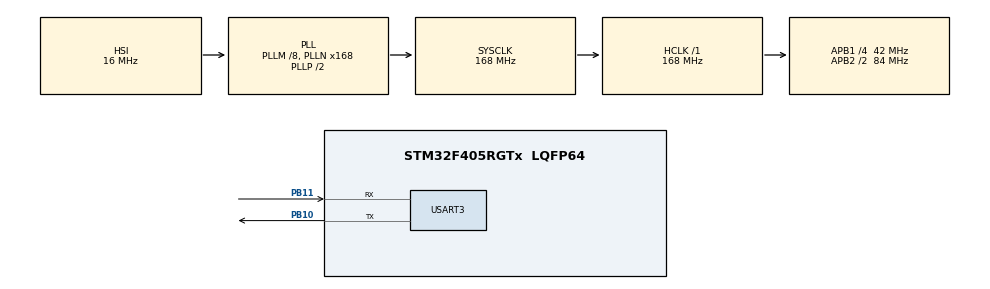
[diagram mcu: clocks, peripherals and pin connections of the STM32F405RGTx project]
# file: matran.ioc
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Mcu.Family=STM32F4
Mcu.Name=STM32F405RGTx
Mcu.Package=LQFP64
NVIC.PriorityGroup=NVIC_PRIORITYGROUP_4
PA13.Mode=Serial_Wire
PA13.Signal=SYS_JTMS-SWDIO
PA14.Mode=Serial_Wire
PA14.Signal=SYS_JTCK-SWCLK
PB10.Mode=Asynchronous
PB10.Signal=USART3_TX
PB11.Mode=Asynchronous
PB11.Signal=USART3_RX
PH0-OSC_IN.Mode=HSE-External-Oscillator
PH0-OSC_IN.Signal=RCC_OSC_IN
PH1-OSC_OUT.Mode=HSE-External-Oscillator
PH1-OSC_OUT.Signal=RCC_OSC_OUT
ProjectManager.HeapSize=0x200
ProjectManager.StackSize=0x400
ProjectManager.TargetToolchain=STM32CubeIDE
RCC.48MHZClocksFreq_Value=84000000
RCC.AHBFreq_Value=168000000
RCC.APB1CLKDivider=RCC_HCLK_DIV4
RCC.APB1Freq_Value=42000000
RCC.APB1TimFreq_Value=84000000
RCC.APB2CLKDivider=RCC_HCLK_DIV2
RCC.APB2Freq_Value=84000000
RCC.APB2TimFreq_Value=168000000
RCC.CortexFreq_Value=168000000
RCC.HCLKFreq_Value=168000000
RCC.HSE_VALUE=12000000
RCC.HSI_VALUE=16000000
RCC.LSE_VALUE=32768
RCC.PLLM=8
RCC.PLLN=168
RCC.SYSCLKFreq_VALUE=168000000
RCC.SYSCLKSource=RCC_SYSCLKSOURCE_PLLCLK
RCC.VCOOutputFreq_Value=336000000
USART3.VirtualMode=VM_ASYNC
board=custom

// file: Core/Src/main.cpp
/*
 * main.cpp
 *
 *  Created on: Feb 7, 2020
 *      Author: tung
 */
/* USER CODE BEGIN Header */
/**
  ******************************************************************************
  * @file           : main.c
  * @brief          : Main program body
  ******************************************************************************
  * @attention
  *
  * <h2><center>&copy; Copyright (c) 2020 STMicroelectronics.
  * All rights reserved.</center></h2>
  *
  * This software component is licensed by ST under BSD 3-Clause license,
  * the "License"; You may not use this file except in compliance with the
  * License. You may obtain a copy of the License at:
  *                        opensource.org/licenses/BSD-3-Clause
  *
  ******************************************************************************
  */
/* USER CODE END Header */

#include "main.h"

/* USER CODE BEGIN Includes */
#include "Matrix.hpp"
/* USER CODE END Includes */

void SystemClock_Config(void);
static void MX_GPIO_Init(void);
static void MX_USART3_UART_Init(void);

/* USER CODE BEGIN 0 */
UART_HandleTypeDef huart3;
/* USER CODE END 0 */

int main(void)
{

  /* MCU Configuration--------------------------------------------------------*/

  /* Reset of all peripherals, Initializes the Flash interface and the Systick. */
  HAL_Init();

  /* Configure the system clock */
  SystemClock_Config();

  /* Initialize all configured peripherals */
  MX_GPIO_Init();
  MX_USART3_UART_Init();
  /* USER CODE BEGIN 2 */
  double x [7] = {1,1,1,1,1,1,1};
  double a [9] = {0,1,2,3,4,5,6,7,8};
  double Q[49]= {  1,0,0,0,0,0,0,
          0,1,0,0,0,0, 0,
           0,0,3,0,0,0,0,
            0,0,0,4,0,0,0,
  		  0,0, 0 ,0 ,5 ,0, 0,
            0,0,0,0,0,6,0,
            0,0,0,0,0,0,7};
  /* USER CODE END 2 */
  Matrix q = Matrix(7,7);
  Matrix s_trans = Matrix(4,3);
  Matrix in = Matrix(3,3);
  in.get_value(a);
  Matrix temp = inverse(in);
  temp.print(huart3);
  Matrix x_ = Matrix(1,7);
  x_.get_value(x);
  q.get_value(Q);
  x_.print(huart3);
  q.print(huart3);
//
  Matrix a_ =  mul_mat(x_, q);
//  a_.print(huart3);

  /* Infinite loop */
  while (1)
  {

    /* USER CODE BEGIN 3 */

//      Matrix p = inverse(q);

//      p.print(huart3);
//      q.print(huart3);
      HAL_Delay(100);
  }
  /* USER CODE END 3 */
}

void SystemClock_Config(void)
{
  RCC_OscInitTypeDef RCC_OscInitStruct = {0};
  RCC_ClkInitTypeDef RCC_ClkInitStruct = {0};

  /** Configure the main internal regulator output voltage
  */
  __HAL_RCC_PWR_CLK_ENABLE();
  __HAL_PWR_VOLTAGESCALING_CONFIG(PWR_REGULATOR_VOLTAGE_SCALE1);
  /** Initializes the CPU, AHB and APB busses clocks
  */
  RCC_OscInitStruct.OscillatorType = RCC_OSCILLATORTYPE_HSI;
  RCC_OscInitStruct.HSIState = RCC_HSI_ON;
  RCC_OscInitStruct.HSICalibrationValue = RCC_HSICALIBRATION_DEFAULT;
  RCC_OscInitStruct.PLL.PLLState = RCC_PLL_ON;
  RCC_OscInitStruct.PLL.PLLSource = RCC_PLLSOURCE_HSI;
  RCC_OscInitStruct.PLL.PLLM = 8;
  RCC_OscInitStruct.PLL.PLLN = 168;
  RCC_OscInitStruct.PLL.PLLP = RCC_PLLP_DIV2;
  RCC_OscInitStruct.PLL.PLLQ = 4;
  if (HAL_RCC_OscConfig(&RCC_OscInitStruct) != HAL_OK)
  {
    Error_Handler();
  }
  /** Initializes the CPU, AHB and APB busses clocks
  */
  RCC_ClkInitStruct.ClockType = RCC_CLOCKTYPE_HCLK|RCC_CLOCKTYPE_SYSCLK
                              |RCC_CLOCKTYPE_PCLK1|RCC_CLOCKTYPE_PCLK2;
  RCC_ClkInitStruct.SYSCLKSource = RCC_SYSCLKSOURCE_PLLCLK;
  RCC_ClkInitStruct.AHBCLKDivider = RCC_SYSCLK_DIV1;
  RCC_ClkInitStruct.APB1CLKDivider = RCC_HCLK_DIV4;
  RCC_ClkInitStruct.APB2CLKDivider = RCC_HCLK_DIV2;

  if (HAL_RCC_ClockConfig(&RCC_ClkInitStruct, FLASH_LATENCY_5) != HAL_OK)
  {
    Error_Handler();
  }
}

/* USER CODE BEGIN 4 */
static void MX_USART3_UART_Init(void)
{

  /* USER CODE BEGIN USART3_Init 0 */

  /* USER CODE END USART3_Init 0 */

  /* USER CODE BEGIN USART3_Init 1 */

  /* USER CODE END USART3_Init 1 */
  huart3.Instance = USART3;
  huart3.Init.BaudRate = 115200;
  huart3.Init.WordLength = UART_WORDLENGTH_8B;
  huart3.Init.StopBits = UART_STOPBITS_1;
  huart3.Init.Parity = UART_PARITY_NONE;
  huart3.Init.Mode = UART_MODE_TX_RX;
  huart3.Init.HwFlowCtl = UART_HWCONTROL_NONE;
  huart3.Init.OverSampling = UART_OVERSAMPLING_16;
  if (HAL_UART_Init(&huart3) != HAL_OK)
  {
    Error_Handler();
  }
  /* USER CODE BEGIN USART3_Init 2 */

  /* USER CODE END USART3_Init 2 */

}

/**
  * @brief GPIO Initialization Function
  * @param None
  * @retval None
  */
static void MX_GPIO_Init(void)
{

  /* GPIO Ports Clock Enable */
  __HAL_RCC_GPIOH_CLK_ENABLE();
  __HAL_RCC_GPIOB_CLK_ENABLE();
  __HAL_RCC_GPIOA_CLK_ENABLE();

}

/* USER CODE END 4 */

void Error_Handler(void)
{
}

/************************ (C) COPYRIGHT STMicroelectronics *****END OF FILE****/
